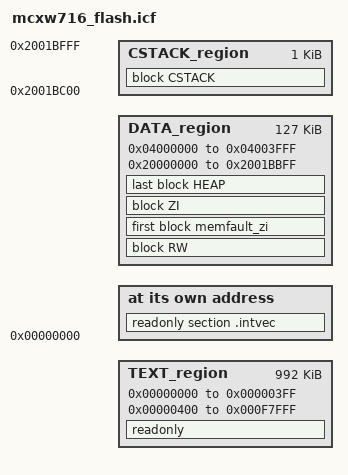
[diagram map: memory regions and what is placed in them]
/*
** ###################################################################
**     Processors:          MCXW716AMFPA
**                          MCXW716AMFTA
**                          MCXW716CMFPA
**                          MCXW716CMFTA
**
**     Compiler:            IAR ANSI C/C++ Compiler for ARM
**     Reference manual:    Rev. 2, Jan. 6, 2022
**     Version:             rev. 1.0, 2024-03-21
**     Build:               b240322
**
**     Abstract:
**         Linker file for the IAR ANSI C/C++ Compiler for ARM
**
**     Copyright 2016 Freescale Semiconductor, Inc.
**     Copyright 2016-2024 NXP
**     SPDX-License-Identifier: BSD-3-Clause
**
**     http:                 www.nxp.com
**     mail:                 support@nxp.com
**
** ###################################################################
*/


/* Stack and Heap Sizes */
if (isdefinedsymbol(__stack_size__)) {
  define symbol __size_cstack__        = __stack_size__;
} else {
  define symbol __size_cstack__        = 0x0400;
}

if (isdefinedsymbol(__heap_size__)) {
  define symbol __size_heap__          = __heap_size__;
} else {
  define symbol __size_heap__          = 0x0800;
}

define symbol m_interrupts_start               = 0x00000000;
define symbol m_interrupts_end                 = 0x000003FF;

define symbol m_text_start                     = 0x00000400;
define symbol m_text_end                       = 0x000FFFFF - 0x8000; /* 32K(0x8000) at the end reserved for memfault */

define symbol m_data0_start                     = 0x04000000;
define symbol m_data0_end                       = 0x04003FFF;

define symbol m_data1_start                     = 0x20000000;
define symbol m_data1_end                       = 0x2001BFFF - __size_cstack__;

define symbol m_stack_start                    = 0x2001C000 - __size_cstack__;
define symbol m_stack_end                      = 0x2001BFFF;

define memory mem with size = 4G;

define region TEXT_region             = mem:[from m_interrupts_start to m_interrupts_end]
                                      | mem:[from m_text_start to m_text_end];
define region DATA_region             = mem:[from m_data0_start to m_data0_end]
                                      | mem:[from m_data1_start to m_data1_end];
define region CSTACK_region           = mem:[from m_stack_start to m_stack_end];

define block CSTACK    with alignment = 8, size = __size_cstack__   { };
define block HEAP      with alignment = 8, size = __size_heap__     { };
define block RW        { readwrite };
define block ZI        { zi };
define block memfault_zi {
    zi object tasks*.o,
    zi object timers*.o,
};

initialize by copy {
    readwrite,
    section .textrw,
    readonly object mflash_drv.o
};

if (isdefinedsymbol(__USE_DLIB_PERTHREAD))
{
  /* Required in a multi-threaded application */
  initialize by copy with packing = none { section __DLIB_PERTHREAD };
}

do not initialize  {
    section .noinit,
    rw section .noinit.mflt*,
};

place at address mem: m_interrupts_start    { readonly section .intvec };
place in TEXT_region                        { readonly };
place in DATA_region                        { block RW };
place in DATA_region                        { first block memfault_zi, block ZI };
place in DATA_region                        { last block HEAP };
place in CSTACK_region                      { block CSTACK };
